# IWRL6432 register map
File version: 1.0
CPU: CM4 1.0, other endian, MPU, FPU, 3 interrupt priority bits
Registers are 32-bit, read-write, reset 0x0 unless marked. A register's access mark holds for its fields unless they carry their own. Offsets are from the block's base; [hi:lo] are bit positions; {n}, {i} and the like mark numbered series.

## APP_RTI
Base 0x56F7F000
Same registers: APP_WD 0x56F7F400
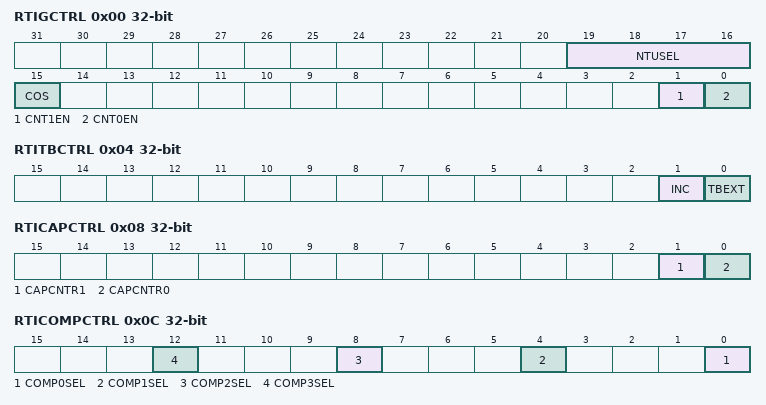
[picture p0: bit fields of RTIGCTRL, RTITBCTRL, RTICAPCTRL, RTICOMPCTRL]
0x00 RTIGCTRL — Global Control Register starts / stops the counters
  [19:16] NTUSEL — [19:16] NTUSEL: Select NTU signal. These bits determine which NTU input signal is used as external timebase. There are up to four inputs supported with four valid selection combinations. Any invalid selection value written to the NTUSEL bit-field will result in a TIED LOW being used as the NTU signal. The NTU signal will also be TIED LOW in case of a single-bit flip as it will result in an invalid combination of NTUSEL. User and privilege mode (read): 0000 = NTU0 0101 = NTU1 1010 = NTU2 1111 = NTU3 other = tied to ΓÇÿ0ΓÇÖ Privilege mode (write): 0000 = NTU0 0101 = NTU1 1010 = NTU2 1111 = NTU3 other = tied to ΓÇÿ0ΓÇÖ
  [15] COS — [15:15] COS: Continue On Suspend. This bit determines if both counters are stopped when the device goes into debug mode or if they continue counting. User and privilege mode (read): 0 = counters are stopped while in debug mode 1 = counters are running while in debug mode Privilege mode (write): 0 = stop counters in debug mode 1 = continue counting in debug mode
  [1] CNT1EN — [1:1] CNT1EN: Counter 1 Enable. The CNT1EN bit starts and stops the operation of counter block 1 (UC1 and FRC1). User and privilege mode (read): 0 = counters are stopped 1 = counters are running Privilege mode (write): 0 = stop counters 1 = start counters Gives the absolute 32 bit destination address (physical).
  [0] CNT0EN — [0:0] CNT0EN: Counter 0 Enable.The CNT0EN bit starts and stops the operation of counter block 0 (UC0 and FRC0). User and privilege mode (read): 0 = counters are stopped 1 = counters are running Privilege mode (write): 0 = stop counters 1 = start counters Gives the absolute 32 bits source address (physical).
0x04 RTITBCTRL — Timebase Control selection which source triggers free running counter 0
  [1] INC — [1:1] INC: Increment Free Running Counter 0. This bit determines wether the Free Running Counter 0 is automatically incremented if a failing clock on the NTUx signal is detected. User and privilege mode (read): 0 = FRC0 will not be incremented 1 = FRC0 will be incremented Privilege mode (write): 0 = Do not increment FRC0 on failing external clock 1 = Increment FRC0 on failing external clock
  [0] TBEXT — [0:0] TBEXT: Timebase External. The Timebase External bit selects whether the Free Running Counter 0 is clocked by the internal Up Counter 0 or from the external signal NTUx. Since setting the TBEXT bit to 1 resets Up Counter 0, Free Running Counter 0 will not be incremented in this occurence. The only source which is able to increment Free Running Counter 0 is NTUx. When the Timebase Supervisor circuit detects a missing clockedge, then the TBEXT bit is reset. The selection if the external signal should be used, can only be done by software. User and privilege mode (read): 0 = UC0 clocks FRC0 1 = NTUx clocks FRC0 Privilege mode (write): 0 = MUX is switched to internal UC0 clocking scheme 1 = MUX is switched to external NTUx clocking scheme
0x08 RTICAPCTRL — Capture Control controls the capture source for the counters
  [1] CAPCNTR1 — [1:1] CAPCNTR1: Capture Counter 1. This bit determines, which external interrupt source triggers a capture event of both UC1 and FRC1. User and privilege mode (read): 0 = capture event is triggered by Capture Event Source 0 1 = capture event is triggered by Capture Event Source 1 Privilege mode (write): 0 = enable capture event triggered by Capture Event Source 0 1 = enable capture event triggered by Capture Event Source 1
  [0] CAPCNTR0 — [0:0] CAPCNTR0: Capture Counter 0. This bit determines, which external interrupt source triggers a capture event of both UC0 and FRC0. User and privilege mode (read): 0 = capture event is triggered by Capture Event Source 0 1 = capture event is triggered by Capture Event Source 1 Privilege mode (write): 0 = enable capture event triggered by Capture Event Source 0 1 = enable capture event triggered by Capture Event Source 1 11 indexed 10 reserved 01 post-increment 00 constant
0x0C RTICOMPCTRL — Compare Control controls the source for the compare registers
  [4n] COMP{n}SEL (n=0..3) — [{4n}:{4n}] COMPSEL{n}: Compare Select {n}. This bit determines the counter with which the compare value hold in compare register {n} is compared. User and privilege mode (read): 0 = value will be compared with FRC 0 1 = value will be compared with FRC 1 Privilege mode (write): 0 = enable compare with FRC 0 1 = enable compare with FRC 1
0x10 RTIFRC0 — Free Running Counter 0 current value of free running counter 0
  [31:0] FRC0 — [31:0] FRC0: Free Running Counter 0. This registers holds the current value of the Free Running Counter 0 and will be updated continuously. User and privilege mode (read): current value of the counter Privilege mode (write): The counter can be preset by writing to this register. The counter increments then from this written value upwards. Note: Presetting counters If counters have to be preset, they have to be stopped from counting in the RTIGCTRL register in order to ensure consistency between RTIUC0 and RTIFRC0.
0x14 RTIUC0 — Up Counter 0 current value of prescale counter 0
  [31:0] UC0 — [31:0] UC0: Up Counter 0. This registers holds the current value of the Up Counter 0 and prescales the RTI clock. It will be only updated by a previous read of Free Running Counter 0. This gives effectively a 64 bit read of both counters, without having the problem of a counter being updated between two consecutive reads on Up Counter 0 and Free Running Counter 0. User and privilege mode (read): value of the counter when the Free Running Counter 0 was read Privilege mode (write): the counter can be preset by writing to this register. The counter increments then from this written value upwards. Note: Presetting counters If counters have to be preset, they have to be stopped from counting in the RTIGCTRL register in order to ensure consistency between RTIUC0 and RTIFRC0. Note: Preset value concern If the preset value is bigger than the compare value stored in register RTICPUC0 then it can take a long time until a compare matches, since RTIUC0 has to count up until it overflows.
0x18 RTICPUC0 — Compare Up Counter 0 compare value compared with prescale counter 0
  [31:0] CPUC0 — [31:0] This registers holds the compare value, which is compared with the Up Counter 0. When the compare matches, Free Running counter 0 is incremented. The Up Counter is set to zero when the counter value matches the CPUC0 value. The value set in this prescales the RTI clock. If CPUC0 = 0: then, frequency = RTICLK/ (2^32) If CPUC0 Γëá 0: then , frequency = RTICLK/(CPUC0 + 1) User and privilege mode (read): current compare value Privilege mode (write when TBEXT = 0): the compare value is updated Privilege mode (write when TBEXT = 1): the compare value is not changed
0x20 RTICAFRC0 — Capture Free Running Counter 0 current value of free running counter 0 on external event
  [31:0] CAFRC0 — [31:0] CAFRC0: Capture Free Running Counter 0. This registers captures the current value of the Free Running Counter 0 when a event occurs, controlled by the external capture control block. User and privilege mode (read): value of Free Running Counter 0 on a capture event
0x24 RTICAUC0 — Capture Up Counter 0 current value of prescale counter 0 on external event
  [31:0] CAUC0 — [31:0] CAUC0: Capture Up Counter 0. This registers captures the current value of the Up Counter 0 when a event occurs, controlled by the external capture control block. The read sequence has to be the same as with Up Counter 0 and Free Running Counter 0. So the RTICAFRC0 register has to be read first, before the RTICAUC0 register is read. This sequence ensures that the value of the RTICAUC0 register is the corresponding value to the RTICAFRC0 register, even if another capture event happens in between the two reads. User and privilege mode (read): value of Up Counter 0 on a capture event
0x30 RTIFRC1 — Free Running Counter 1 current value of free running counter 1
  [31:0] FRC1 — [31:0] FRC1: Free Running Counter 1. This registers holds the current value of the Free Running Counter 1 and will be updated continuously. User and privilege mode (read): current value of the counter Privilege mode (write): The counter can be preset by writing to this register. The counter increments then from this written value upwards. Note: Presetting counters If counters have to be preset, they have to be stopped from counting in the RTIGCTRL register in order to ensure consistency between RTIUC1 and RTIFRC1.
0x34 RTIUC1 — Up Counter 1 current value of prescale counter 1
  [31:0] UC1 — [31:0] UC1: Up Counter 1. This registers holds the current value of the Up Counter 1 and prescales the RTI clock. It will be only updated by a previous read of Free Running Counter 1. This gives effectively a 64 bit read of both counters, without having the problem of a counter being updated between two consecutive reads on Up Counter 1 and Free Running Counter 1. User and privilege mode (read): value of the counter when the Free Running Counter 1 was read Privilege mode (write): the counter can be preset by writing to this register. The counter increments then from this written value upwards. Note: Presetting counters If counters have to be preset, they have to be stopped from counting in the RTIGCTRL register in order to ensure consistency between RTIUC1 and RTIFRC1. Note: Preset value concern If the preset value is bigger than the compare value stored in register RTICPUC1 then it can take a long time until a compare matches, since RTIUC1 has to count up until it overflows.
0x38 RTICPUC1 — Compare Up Counter 1 compare value compared with prescale counter 1
  [31:0] CPUC1 — [31:0] This registers holds the compare value, which is compared with the Up Counter 1. When the compare matches, Free Running Counter 1 is incremented. The Up Counter is set to zero when the counter value matches the CPUC1 value. The value set in this prescales the RTI clock. If CPUC1 = 0: then, frequency = RTICLK/ (2^32) If CPUC1 Γëá 0: then , frequency = RTICLK/(CPUC1 + 1) User and privilege mode (read): current compare value Privilege mode (write when TBEXT = 0): the compare value is updated Privilege mode (write when TBEXT = 1): the compare value is not changed
0x40 RTICAFRC1 — Capture Free Running Counter 1 current value of free running counter 1 on external event
  [31:0] CAFRC1 — [31:0] CAFRC1: Capture Free Running Counter 1. This registers captures the current value of the Free Running Counter 1 when a event occurs, controlled by the external capture control block. User and privilege mode (read): value of Free Running Counter 1 on a capture event
0x44 RTICAUC1 — Capture Up Counter 1 current value of prescale counter 1 on external event
  [31:0] CAUC1 — [31:0] CAUC1: Capture Up Counter 1. This registers captures the current value of the Up Counter 1 when a event occurs, controlled by the external capture control block. The read sequence has to be the same as with Up Counter 1 and Free Running Counter 1. So the RTICAFRC1 register has to be read first, before the RTICAUC1 register is read. This sequence ensures that the value of the RTICAUC1 register is the corresponding value to the RTICAFRC1 register, even if another capture event happens in between the two reads. User and privilege mode (read): value of Up Counter 1 on a capture event
0x50 RTICOMP0 — Compare 0 compare value to be compared with the counters
  [31:0] COMP0 — [31:0] COMP0: Compare 0. This registers holds a compare value, which is compared with the counter selected in the compare control logic. If the Free Running Counter matches the compare value, an interrupt is flagged. With this register it is also possible to initiate a DMA request. User and privilege mode (read): current compare value Privilege mode (write): update of the compare register with a new compare value Note: Reset behavior A reset does not generate a compare match, since the compare logic will only be active, when the associated counter block is enabled.
0x54 RTIUDCP0 — Update Compare 0 value to be added to the compare register 0 value on compare match
  [31:0] UDCP0 — [31:0] UDCP0: Update Compare 0 Register. This registers holds a value, which is added to the value in the compare 0 register each time a compare matches. This gives the possibility to generate periodic interrupts without software intervention. User and privilege mode (read): value to be added to the compare 0 register on the next compare match Privilege mode (write): new update value
0x58 RTICOMP1 — Compare 1 compare value to be compared with the counters
  [31:0] COMP1 — [31:0] COMP1: compare1. This registers holds a compare value, which is compared with the counter selected in the compare control logic. If the Free Running Counter matches the compare value, an interrupt is flagged. With this register it is also possible to initiate a DMA request. User and privilege mode (read): current compare value Privilege mode (write): update of the compare register with a new compare value Note: Reset behavior A reset does not generate a compare match, since the compare logic will only be active, when the associated counter block is enabled.
0x5C RTIUDCP1 — Update Compare 1 value to be added to the compare register 1 value on compare match
  [31:0] UDCP1 — [31:0] UDCP1: Update compare1 Register. This registers holds a value, which is added to the value in the compare1 register each time a compare matches. This gives the possibility to generate periodic interrupts without software intervention. User and privilege mode (read): value to be added to the compare1 register on the next compare match Privilege mode (write): new update value
0x60 RTICOMP2 — Compare 2 compare value to be compared with the counters
  [31:0] COMP2 — [31:0] COMP2: compare 2. This registers holds a compare value, which is compared with the counter selected in the compare control logic. If the Free Running Counter matches the compare value, an interrupt is flagged. With this register it is also possible to initiate a DMA request. User and privilege mode (read): current compare value Privilege mode (write): update of the compare register with a new compare value Note: Reset behavior A reset does not generate a compare match, since the compare logic will only be active, when the associated counter block is enabled.
0x64 RTIUDCP2 — Update Compare 2 value to be added to the compare register 2 value on compare match
  [31:0] UDCP2 — [31:0] UDCP2: Update compare 2 Register. This registers holds a value, which is added to the value in the compare 2 register each time a compare matches. This gives the possibility to generate periodic interrupts without software intervention. User and privilege mode (read): value to be added to the compare 2 register on the next compare match Privilege mode (write): new update value
0x68 RTICOMP3 — Compare 3 compare value to be compared with the counters
  [31:0] COMP3 — [31:0] COMP3: compare 3. This registers holds a compare value, which is compared with the counter selected in the compare control logic. If the Free Running Counter matches the compare value, an interrupt is flagged. With this register it is also possible to initiate a DMA request. User and privilege mode (read): current compare value Privilege mode (write): update of the compare register with a new compare value Note: Reset behavior A reset does not generate a compare match, since the compare logic will only be active, when the associated counter block is enabled.
0x6C RTIUDCP3 — Update Compare 3 value to be added to the compare register 3 value on compare match
  [31:0] UDCP3 — [31:0] UDCP3: Update compare 3 Register. This registers holds a value, which is added to the value in the compare 3 register each time a compare matches. This gives the possibility to generate periodic interrupts without software intervention. User and privilege mode (read): value to be added to the compare 3 register on the next compare match Privilege mode (write): new update value
0x70 RTITBLCOMP — Timebase Low Compare compare value to activate edge detection circuit
  [31:0] TBLCOMP — [31:0] TBLCOMP: Timebase Low Compare Value. This value determines when the edge detection circuit starts monitoring the NTUx signal. It will be compared with Up Counter 0. User and privilege mode (read): current compare value Privilege mode (write when TBEXT = 0): the compare value is updated Privilege mode (write when TBEXT = 1): the compare value is not changed Note: Reset behavior A reset does not generate a compare match.
0x74 RTITBHCOMP — Timebase High Compare compare value to deactivate edge detection circuit
  [31:0] TBHCOMP — [31:0] TBHCOMP: Timebase High Compare Value. This value determines when the edge detection circuit will stop monitoring the NTUx signal. It will be compared with Up Counter 0. RTITBHCOMP has to be less than RTICPUC0, since RTIUC0 will be reset when RTICPUC0 is reached. Example: The NTUx edge detection circuit should be active +/- 10 RTICLK cycles around RTICPUC0. RTICPUC0 = 0x00000050 RTITBLCOMP = 0x000046 RTITBHCOMP = 0x00000009 User and privilege mode (read): current compare value Privilege mode (write when TBEXT = 0): the compare value is updated Privilege mode (write when TBEXT = 1): the compare value is not changed Note: Reset behavior A reset does not generate a compare match.
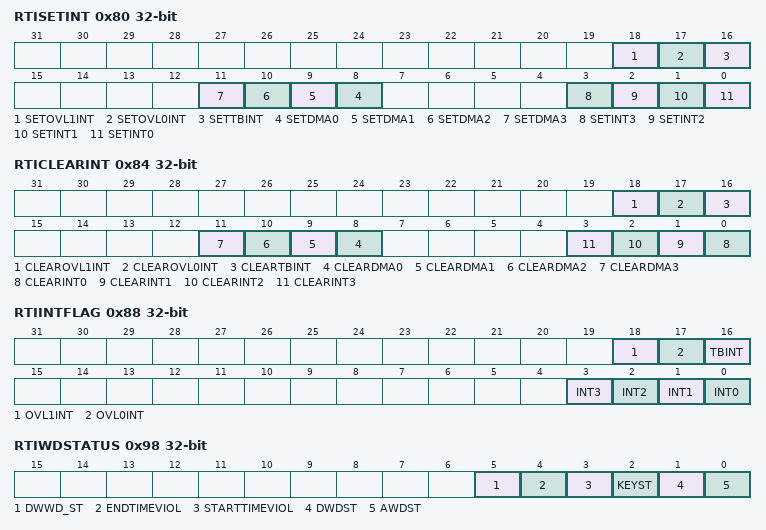
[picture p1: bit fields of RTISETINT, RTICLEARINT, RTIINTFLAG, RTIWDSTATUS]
0x80 RTISETINT — Set Interrupt Enable sets interrupt enable bits int RTIINTCTRL without having to do a read-modify-write operation
  [18] SETOVL1INT — [18:18] SETOVL1INT: Set Free Running Counter 1 Overflow Interrupt. User and privilege mode (read): 0 = interrupt is disabled 1 = interrupt is enabled Privilege mode (write): 0 = leaves the corresponding bit unchanged 1 = enable interrupt
  [17] SETOVL0INT — [17:17] SETOVL0INT: Set Free Running Counter 0 Overflow Interrupt. User and privilege mode (read): 0 = interrupt is disabled 1 = interrupt is enabled Privilege mode (write): 0 = leaves the corresponding bit unchanged 1 = enable interrupt
  [16] SETTBINT — [16:16] SETTBINT: Set Timebase Interrupt. User and privilege mode (read): 0 = interrupt is disabled 1 = interrupt is enabled Privilege mode (write): 0 = leaves the corresponding bit unchanged 1 = enable interrupt
  [n+8] SETDMA{n} (n=0..3) — [{n+8}:{n+8}] SETDMA{n}: Set Compare DMA Request {n}. User and privilege mode (read): 0 = DMA request is disabled 1 = DMA request is enabled Privilege mode (write): 0 = leaves the corresponding bit unchanged 1 = enable DMA request
  [3] SETINT3 — [3:3] SETINT3: Set Compare Interrupt 3. User and privilege mode (read): 0 = interrupt is disabled 1 = interrupt is enabled Privilege mode (write): 0 = leaves the corresponding bit unchanged
  [2] SETINT2 — [2:2] SETINT2: Set Compare Interrupt 2. User and privilege mode (read): 0 = interrupt is disabled 1 = interrupt is enabled Privilege mode (write): 0 = leaves the corresponding bit unchanged 1 = enable interrupt
  [1] SETINT1 — [1:1] SETINT1: Set Compare Interrupt 1. User and privilege mode (read): 0 = interrupt is disabled 1 = interrupt is enabled Privilege mode (write): 0 = leaves the corresponding bit unchanged 1 = enable interrupt
  [0] SETINT0 — [0:0] SETINT0: Set Compare Interrupt 0. User and privilege mode (read): 0 = interrupt is disabled 1 = interrupt is enabled Privilege mode (write): 0 = leaves the corresponding bit unchanged 1 = enable interrupt
0x84 RTICLEARINT — Clear Interrupt Enable clears interrupt enable bits int RTIINTCTRL without having to do a read-modify-write operation
  [18] CLEAROVL1INT — [18:18] CLEAROVL1INT: CLEAR Free Running Counter 1 Overflow Interrupt. User and privilege mode (read): 0 = interrupt is disabled 1 = interrupt is enabled Privilege mode (write): 0 = leaves the corresponding bit unchanged 1 = disable interrupt
  [17] CLEAROVL0INT — [17:17] CLEAROVL0INT: CLEAR Free Running Counter 0 Overflow Interrupt. User and privilege mode (read): 0 = interrupt is disabled 1 = interrupt is enabled Privilege mode (write): 0 = leaves the corresponding bit unchanged 1 = disable interrupt
  [16] CLEARTBINT — [16:16] CLEARTBINT: CLEAR Timebase Interrupt. User and privilege mode (read): 0 = interrupt is disabled 1 = interrupt is enabled Privilege mode (write): 0 = leaves the corresponding bit unchanged 1 = disable interrupt
  [n+8] CLEARDMA{n} (n=0..3) — [{n+8}:{n+8}] CLEARDMA{n}: CLEAR Compare DMA Request {n}. User and privilege mode (read): 0 = DMA request is disabled 1 = DMA request is enabled Privilege mode (write): 0 = leaves the corresponding bit unchanged 1 = disable DMA request
  [n] CLEARINT{n} (n=0..3) — [{n}:{n}] CLEARINT{n}: CLEAR Compare Interrupt {n}. User and privilege mode (read): 0 = interrupt is disabled 1 = interrupt is enabled Privilege mode (write): 0 = leaves the corresponding bit unchanged 1 = disable interrupt
0x88 RTIINTFLAG — Interrupt Flags interrupt pending bits
  [18] OVL1INT — [18:18] OVL1INT: Free Running Counter 1 Overflow Interrupt Flag. User and privilege mode (read): determines if an interrupt is pending 0 = no interrupt pending 1 = interrupt pending Privilege mode (write): 0 = leaves the bit unchanged 1 = set the bit to 0
  [17] OVL0INT — [17:17] OVL0INT: Free Running Counter 0 Overflow Interrupt Flag. User and privilege mode (read): determines if an interrupt is pending 0 = no interrupt pending 1 = interrupt pending Privilege mode (write): 0 = leaves the bit unchanged 1 = set the bit to 0
  [16] TBINT — [16:16] User and privilege mode (read): this flag is set when the TBEXT bit is cleared by detection of a missing external clockedge. It will not be set by clearing TBEXT by software. determines if an interrupt is pending 0 = no interrupt pending 1 = interrupt pending Privilege mode (write): 0 = leaves the bit unchanged 1 = set the bit to 0
  [n] INT{n} (n=0..3) — [{n}:{n}] INT{n}: Interrupt Flag {n}. User and privilege mode (read): determines if a interrupt is pending 0 = no interrupt pending 1 = interrupt pending Privilege mode (write): 0 = leaves the bit unchanged 1 = set the bit to 0
0x90 RTIDWDCTRL — Digital Watchdog Control Enables the Digital Watchdog
  [31:0] DWDCTRL — [31:0] DWDCTRL: Digital Watchdog Control. User and priviledge mode (read): 0x5312ACED = DWD counter is disabled. This is the default value. 0xA98559DA = DWD counter is enabled Any other value = DWD counter state is unchanged (enabled or disabled) Priviledge mode (write): 0xA98559DA = DWD counter is enabled Any other value = State of DWD counter is unchanged (stays enabled or disabled) Note: One-Write Functionality of DWDCTRL Register The RTIDWDCTRL register implements a one-write functionality, such that the application cannot write to this registermore than once. Writing the default value will not enable the watchdog as described above. Writing the enable value will start the watchdog counters. A write to RTIDWDCTRL will only be enabled after a system reset again.
0x94 RTIDWDPRLD — Digital Watchdog Preload sets the experation time of the Digital Watchdog
  [11:0] DWDPRLD — [11:0] DWDPRLD: Digital Watchdog Preload Value. User and priviledge mode (read): A read from this register in any CPU mode returns the current preload value. Priviledge mode (write): If the DWD is always enabled after reset is released: The DWD starts counting down from the reset value of the counter, that is, 0x002DFFFF. The application can configure the DWD preload register any time before this down counter expires. When the application services the DWD, the preload register contents are copied left-justified into the DWD down counter and it starts counting down from that value. If the DWD is implemented such that the down counter is enabled by software: The DWD preload register can be configured only when the DWD is disabled. Therefore, the application can only configure the DWD preload register before it enables the DWD down counter. The expiration time of the DWD Down Counter can be determined with following equation: texp = (RTIDWDPRLD+1) x 2 ^ 13 / RTICLK1 where: RTIDWDPRLD = 0...4095
0x98 RTIWDSTATUS — Watchdog Status reflects the status of Analog and Digital Watchdog
  [5] DWWD_ST — [5:5] DWWD ST: Windowed Watchdog Status. This bit denotes whether the time-window defined by the windowed watchdog configuration has been violated, or if a wrong key or key sequence was written to service the watchdog. User and priviledge mode (read): 0 = no time-window violation has occurred. 1 = a time-window violation has occurred. The watchdog will generate either a system reset or a non-maskable interrupt to the CPU in this case. Priviledge mode (write): 0 = leaves the current value unchanged. 1 = clears the bit to 0. This will also clear all other status flags in the RTIWDSTATUS register except for the AWD ST flag. Clearing of the status flags will deassert the non-maskable interrupt generated due to violation of the DWWD.
  [4] ENDTIMEVIOL — [4:4] END TIME VIOL: Windowed Watchdog End Time Violation Status. This bit denotes whether the end-time defined by the windowed watchdog configuration has been violated. This bit is effectively a copy of the DWD ST status flag. User and priviledge mode (read): 0 = no end-time window violation has occurred. 1 = the end-time defined by the windowed watchdog configuration has been violated. Priviledge mode (write): 0 = leaves the current value unchanged. 1 = clears the bit to 0.
  [3] STARTTIMEVIOL — [3:3] START TIME VIOL: Windowed Watchdog Start Time Violation Status. This bit denotes whether the start-time defined by the windowed watchdog configuration has been violated. This indicates that the WWD was serviced before the service window was opened. User and priviledge mode (read): 0 = no start-time window violation has occurred. 1 = the start-time defined by the windowed watchdog configuration has been violated. Priviledge mode (write): 0 = leaves the current value unchanged. 1 = clears the bit to 0.
  [2] KEYST — [2:2] KEYST: Watchdog KeyStatus. This bit denotes a reset generated by a wrong key or a wrong key-sequence written to the RTIWDKEY register. User and priviledge mode (read): 0 = no wrong key or key-sequence written 1 = wrong key or key-sequence written to RTIWDKEY register Priviledge mode (write): 0 = leaves the current value unchanged 1 = clears the bit to 0
  [1] DWDST — [1:1] DWDST: Digital Watchdog Status. This bit is effectively a copy of the END TIME VIOL status flag and is maintained for compatibility reasons. User and priviledge mode (read): 0 = DWD timeout period not expired 1 = DWD timeout period has expired Priviledge mode (write): 0 = leaves the current value unchanged 1 = clears the bit to 0
  [0] AWDST — [0:0] AWDST: Analog Watchdog Status. User and priviledge mode (read): 0 = AWD pin 0 ΓÇô> 1 threshold not exceeded 1 = AWD pin 0 ΓÇô> 1 threshold exceeded Priviledge mode (write): 0 = leaves the current value unchanged 1 = clears the bit to 0
0x9C RTIWDKEY — Watchdog Key correct written key values discharge the external capacitor
  [15:0] WDKEY — [15:0] WDKEY: Watchdog Key. User and privilege mode reads are indeterminate. Privilege mode (write): A write of 0xE51A followed by 0xA35C in two separate write operations defines the Key Sequence and discharges the watchdog capacitor. This also causes the upper 12 bits of the DWD down counter to be reloaded with the contents of the DWD preload register and the lower 13 bits to become all 1ΓÇÖs. Writing any other value causes a digital watchdog reset, as shown in Table 1-3. Note: Register write access time precaution The user has to take into account that the write to the register takes 3 VCLK cycle. This needs to be considered for the AWD/DWD expiration calculation.
0xA0 RTIDWDCNTR — Digital Watchdog Down Counter current value of DWD down counter
  [24:0] DWDCNTR — [24:0] DWDCNTR: Digital Watchdog Down Counter. The value of the DWDCNTR after a system reset is 0x002D_FFFF. When the DWD is enabled and the DWD counter starts counting down from this value with an RTICLK1 time base of 3MHz, a watchdog reset will be generated in 1 second. User and privilege mode (read): Reads return the current counter value. Privilege mode (write): Writes donΓÇÖt have an effect.
0xA4 RTIWWDRXNCTRL — Windowed Watchdog Reaction Control configures the windowed watchdog to either generate a non-maskable interrupt to the CPU or to generate a system reset
  [3:0] WWDRXN — [3:0] WWDRXN: Digital Windowed Watchdog Reaction. User and privilege mode (read), privileged mode (write): 0x5 = This is the default value. The windowed watchdog will cause a reset if the watchdog is serviced outside the time window defined by the configuration, or if the watchdog is not serviced at all. 0xA = The windowed watchdog will generate a non-maskable interrupt to the CPU if the watchdog is serviced outside the time window defined by the configuration, or if the watchdog is not serviced at all. Writing any other value will cause a system reset if the watchdog is serviced outside the time window defined by the configuration, or if the watchdog is not serviced at all. Note: Configuration of DWWD Reaction The DWWD reaction can be selected by the application even when the DWWD counter is already enabled. If a change to the WWDRXN is made before the watchdog service window is opened, then the change in the configuration takes effect immediately. If a change to the WWDRXN is made when the watchdog service window is already open, then the change in configuration takes effect only after the watchdog is serviced.
0xA8 RTIWWDSIZECTRL — Windowed Watchdog Size Control configures the size of the window for the digital windowed watchdog
  [31:0] WWDSIZE — [31:0] WWDSIZE: Digital Windowed Watchdog Window Size. User and privilege mode (read), privileged mode (write): Value written to WWDSIZE Window Size 0x00000005 100% (Functionality same as the time-out digital watchdog.) 0x00000050 50% 0x00000500 25% 0x00005000 12.5% 0x00050000 6.25% 0x00500000 3.125% Any other value 3.125% Note: Incorrect value being written to watchdog window size control register If an incorerct value is written to the WWDSIZE field, or if a system disturbance causes the WWDSIZE field to have a value other than 0x5, 0x50, 0x500, 0x5000, 0x50000, or 0x500000, then the window size will be configured to be 3.125%. This increases the chances of getting a reset due to the windowed watchdog, which enables the system to handle the cause for the incorrect configuration. Note: Configuration of DWWD Window Size The DWWD window size can be selected by the application even when the DWWD counter is already enabled. If a change to the WWDSIZE is made before the watchdog service window is opened, then the change in the configuration takes effect immediately. If a change to the WWDSIZE is made when the watchdog service window is already open, then
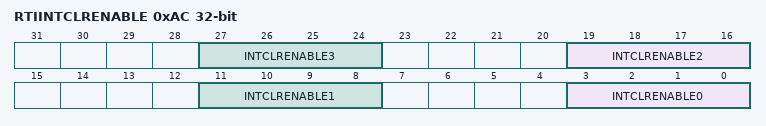
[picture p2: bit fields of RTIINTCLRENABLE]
0xAC RTIINTCLRENABLE — RTI Compare Interrupt Clear Enable enable the auto clear functionality for each of the compare interrupts
  [8n+3:8n] INTCLRENABLE{n} (n=0..3) — [{8n+3}:{8n}] INTCLRENABLE{n}. Enables the auto-clear functionality on the compare {n} interrupt. User and Privileged mode (read): 0x5 = Auto-clear for compare {n} interrupt is disabled. Any other value = Auto-clear for compare {n} interrupt is enabled. Privileged mode (write): 0x5 = Disables the auto-clear functionality on the compare {n} interrupt. Any other value = Enables the auto-clear functionality on the compare {n} interrupt.
0xB0 RTICOMP0CLR — Compare 0 Clear compare value to be compared with the counter to clear the compare0 interrupt line
  [31:0] COMP0CLR — [31:0] COMP0CLR: Compare 0 Clear. This registers holds a compare value, which is compared with the counter selected in the compare control logic. If the Free Running Counter matches the compare value, the compare 0 interrupt or DMA request line is cleared. User and privilege mode (read): current compare value Privilege mode (write): update of the compare register with a new compare value Note: Reset behavior A reset does not generate a compare match, since the compare logic will only be active, when the associated counter block is enabled.
{0xB0+4i} RTICOMP{i}CLR (i=1..3) — Compare {i} Clear compare value to be compared with the counter to clear the compare{i} interrupt line
  [31:0] COMP{i}CLR — [31:0] COMP{i}CLR: Compare {i} Clear. This registers holds a compare value, which is compared with the counter selected in the compare control logic. If the Free Running Counter matches the compare value, the Compare {i} interrupt or DMA request line is cleared. User and privilege mode (read): current compare value Privilege mode (write): update of the compare register with a new compare value Note: Reset behavior A reset does not generate a compare match, since the compare logic will only be active, when the associated counter block is enabled.
